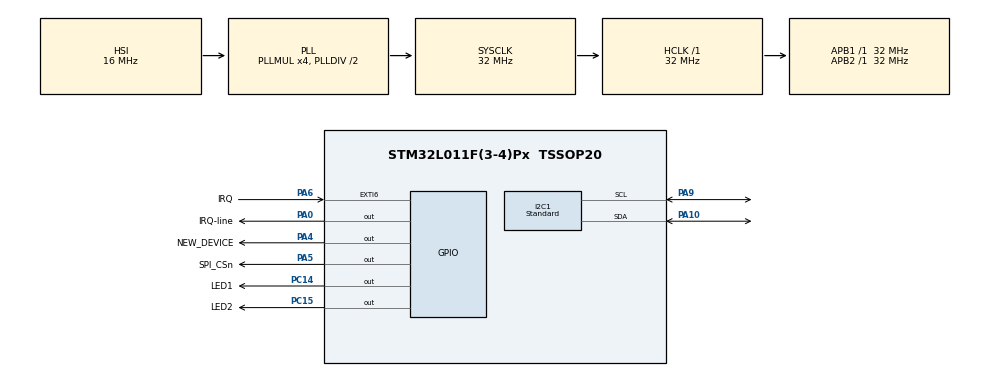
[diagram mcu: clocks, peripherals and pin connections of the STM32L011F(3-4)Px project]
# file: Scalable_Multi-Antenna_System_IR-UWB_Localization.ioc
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I2C1.GeneralCallMode=I2C_GENERALCALL_DISABLE
I2C1.I2C_Speed_Mode=I2C_Standard
I2C1.Timing=0x00707CBB
Mcu.Family=STM32L0
Mcu.Name=STM32L011F(3-4)Px
Mcu.Package=TSSOP20
NVIC.I2C1_IRQn=true\:0\:0\:false\:false\:true\:true\:true
PA0-CK_IN.GPIO_Label=IRQ-line
PA0-CK_IN.GPIO_ModeDefaultOutputPP=GPIO_MODE_OUTPUT_OD
PA0-CK_IN.Signal=GPIO_Output
PA10.Mode=I2C
PA10.Signal=I2C1_SDA
PA13.Mode=Serial_Wire
PA13.Signal=SYS_SWDIO
PA14.Mode=Serial_Wire
PA14.Signal=SYS_SWCLK
PA2.GPIO_Label=WAKEUP
PA2.Mode=SYS_WakeUp2
PA2.Signal=SYS_WKUP3
PA4.GPIO_Label=NEW_DEVICE
PA4.Signal=GPIO_Output
PA5.GPIO_Label=SPI_CSn
PA5.Signal=GPIO_Output
PA6.GPIO_Label=IRQ
PA6.Signal=GPXTI6
PA9.Mode=I2C
PA9.Signal=I2C1_SCL
PC14-OSC32_IN.GPIO_Label=LED1
PC14-OSC32_IN.Signal=GPIO_Output
PC15-OSC32_OUT.GPIO_Label=LED2
PC15-OSC32_OUT.Signal=GPIO_Output
ProjectManager.HeapSize=0x200
ProjectManager.StackSize=0x400
ProjectManager.TargetToolchain=STM32CubeIDE
RCC.AHBFreq_Value=32000000
RCC.APB1Freq_Value=32000000
RCC.APB1TimFreq_Value=32000000
RCC.APB2Freq_Value=32000000
RCC.APB2TimFreq_Value=32000000
RCC.HCLKFreq_Value=32000000
RCC.HSE_VALUE=8000000
RCC.HSI16_VALUE=16000000
RCC.HSI_VALUE=16000000
RCC.LSE_VALUE=32768
RCC.MSI_VALUE=2097000
RCC.PLLMUL=RCC_PLLMUL_4
RCC.SYSCLKFreq_VALUE=32000000
RCC.SYSCLKSource=RCC_SYSCLKSOURCE_PLLCLK
RCC.VCOOutputFreq_Value=64000000
board=custom

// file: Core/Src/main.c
/* USER CODE BEGIN Header */
/**
  ******************************************************************************
  * @file           : main.c
  * @brief          : Main program body
  ******************************************************************************
  * @attention
  *
  * <h2><center>&copy; Copyright (c) 2022 STMicroelectronics.
  * All rights reserved.</center></h2>
  *
  * This software component is licensed by ST under BSD 3-Clause license,
  * the "License"; You may not use this file except in compliance with the
  * License. You may obtain a copy of the License at:
  *                        opensource.org/licenses/BSD-3-Clause
  *
  ******************************************************************************
  */
/* USER CODE END Header */
#include "main.h"

I2C_HandleTypeDef hi2c1;

void SystemClock_Config(void);
static void MX_GPIO_Init(void);
static void MX_I2C1_Init(void);
/* USER CODE BEGIN PFP */

void HAL_GPIO_EXTI_Callback(uint16_t);

/* USER CODE END PFP */

int main(void)
{

  /* MCU Configuration--------------------------------------------------------*/

  /* Reset of all peripherals, Initializes the Flash interface and the Systick. */
  HAL_Init();

  /* Configure the system clock */
  SystemClock_Config();

  /* Initialize all configured peripherals */
  MX_GPIO_Init();
  MX_I2C1_Init();
  /* USER CODE BEGIN 2 */

  HAL_GPIO_WritePin(LED1_GPIO_Port, LED1_Pin, GPIO_PIN_RESET);
  HAL_GPIO_WritePin(LED2_GPIO_Port, LED2_Pin, GPIO_PIN_RESET);

  /* USER CODE END 2 */

  /* Infinite loop */
  while (1)
  {
	  /* TEST CODE: BLINK LEDS */
	  HAL_Delay(1000);
	  HAL_GPIO_TogglePin(LED1_GPIO_Port, LED1_Pin);
	  HAL_GPIO_TogglePin(LED2_GPIO_Port, LED2_Pin);

  }
}

void SystemClock_Config(void)
{
  RCC_OscInitTypeDef RCC_OscInitStruct = {0};
  RCC_ClkInitTypeDef RCC_ClkInitStruct = {0};
  RCC_PeriphCLKInitTypeDef PeriphClkInit = {0};

  /** Configure the main internal regulator output voltage
  */
  __HAL_PWR_VOLTAGESCALING_CONFIG(PWR_REGULATOR_VOLTAGE_SCALE1);
  /** Initializes the RCC Oscillators according to the specified parameters
  * in the RCC_OscInitTypeDef structure.
  */
  RCC_OscInitStruct.OscillatorType = RCC_OSCILLATORTYPE_HSI;
  RCC_OscInitStruct.HSIState = RCC_HSI_ON;
  RCC_OscInitStruct.HSICalibrationValue = RCC_HSICALIBRATION_DEFAULT;
  RCC_OscInitStruct.PLL.PLLState = RCC_PLL_ON;
  RCC_OscInitStruct.PLL.PLLSource = RCC_PLLSOURCE_HSI;
  RCC_OscInitStruct.PLL.PLLMUL = RCC_PLLMUL_4;
  RCC_OscInitStruct.PLL.PLLDIV = RCC_PLLDIV_2;
  if (HAL_RCC_OscConfig(&RCC_OscInitStruct) != HAL_OK)
  {
    Error_Handler();
  }
  /** Initializes the CPU, AHB and APB buses clocks
  */
  RCC_ClkInitStruct.ClockType = RCC_CLOCKTYPE_HCLK|RCC_CLOCKTYPE_SYSCLK
                              |RCC_CLOCKTYPE_PCLK1|RCC_CLOCKTYPE_PCLK2;
  RCC_ClkInitStruct.SYSCLKSource = RCC_SYSCLKSOURCE_PLLCLK;
  RCC_ClkInitStruct.AHBCLKDivider = RCC_SYSCLK_DIV1;
  RCC_ClkInitStruct.APB1CLKDivider = RCC_HCLK_DIV1;
  RCC_ClkInitStruct.APB2CLKDivider = RCC_HCLK_DIV1;

  if (HAL_RCC_ClockConfig(&RCC_ClkInitStruct, FLASH_LATENCY_1) != HAL_OK)
  {
    Error_Handler();
  }
  PeriphClkInit.PeriphClockSelection = RCC_PERIPHCLK_I2C1;
  PeriphClkInit.I2c1ClockSelection = RCC_I2C1CLKSOURCE_PCLK1;
  if (HAL_RCCEx_PeriphCLKConfig(&PeriphClkInit) != HAL_OK)
  {
    Error_Handler();
  }
}

static void MX_I2C1_Init(void)
{

  hi2c1.Instance = I2C1;
  hi2c1.Init.Timing = 0x00707CBB;
  hi2c1.Init.OwnAddress1 = 0;
  hi2c1.Init.AddressingMode = I2C_ADDRESSINGMODE_7BIT;
  hi2c1.Init.DualAddressMode = I2C_DUALADDRESS_DISABLE;
  hi2c1.Init.OwnAddress2 = 0;
  hi2c1.Init.OwnAddress2Masks = I2C_OA2_NOMASK;
  hi2c1.Init.GeneralCallMode = I2C_GENERALCALL_DISABLE;
  hi2c1.Init.NoStretchMode = I2C_NOSTRETCH_DISABLE;
  if (HAL_I2C_Init(&hi2c1) != HAL_OK)
  {
    Error_Handler();
  }
  /** Configure Analogue filter
  */
  if (HAL_I2CEx_ConfigAnalogFilter(&hi2c1, I2C_ANALOGFILTER_ENABLE) != HAL_OK)
  {
    Error_Handler();
  }
  /** Configure Digital filter
  */
  if (HAL_I2CEx_ConfigDigitalFilter(&hi2c1, 0) != HAL_OK)
  {
    Error_Handler();
  }

}

static void MX_GPIO_Init(void)
{
  GPIO_InitTypeDef GPIO_InitStruct = {0};

  /* GPIO Ports Clock Enable */
  __HAL_RCC_GPIOC_CLK_ENABLE();
  __HAL_RCC_GPIOA_CLK_ENABLE();

  /*Configure GPIO pin Output Level */
  HAL_GPIO_WritePin(GPIOC, LED1_Pin|LED2_Pin, GPIO_PIN_RESET);

  /*Configure GPIO pin Output Level */
  HAL_GPIO_WritePin(GPIOA, IRQ_line_Pin|NEW_DEVICE_Pin|SPI_CSn_Pin, GPIO_PIN_RESET);

  /*Configure GPIO pins : LED1_Pin LED2_Pin */
  GPIO_InitStruct.Pin = LED1_Pin|LED2_Pin;
  GPIO_InitStruct.Mode = GPIO_MODE_OUTPUT_PP;
  GPIO_InitStruct.Pull = GPIO_NOPULL;
  GPIO_InitStruct.Speed = GPIO_SPEED_FREQ_LOW;
  HAL_GPIO_Init(GPIOC, &GPIO_InitStruct);

  /*Configure GPIO pin : IRQ_line_Pin */
  GPIO_InitStruct.Pin = IRQ_line_Pin;
  GPIO_InitStruct.Mode = GPIO_MODE_OUTPUT_OD;
  GPIO_InitStruct.Pull = GPIO_NOPULL;
  GPIO_InitStruct.Speed = GPIO_SPEED_FREQ_LOW;
  HAL_GPIO_Init(IRQ_line_GPIO_Port, &GPIO_InitStruct);

  /*Configure GPIO pins : NEW_DEVICE_Pin SPI_CSn_Pin */
  GPIO_InitStruct.Pin = NEW_DEVICE_Pin|SPI_CSn_Pin;
  GPIO_InitStruct.Mode = GPIO_MODE_OUTPUT_PP;
  GPIO_InitStruct.Pull = GPIO_NOPULL;
  GPIO_InitStruct.Speed = GPIO_SPEED_FREQ_LOW;
  HAL_GPIO_Init(GPIOA, &GPIO_InitStruct);

  /*Configure GPIO pin : IRQ_Pin */
  GPIO_InitStruct.Pin = IRQ_Pin;
  GPIO_InitStruct.Mode = GPIO_MODE_IT_RISING;
  GPIO_InitStruct.Pull = GPIO_NOPULL;
  HAL_GPIO_Init(IRQ_GPIO_Port, &GPIO_InitStruct);

}

/* USER CODE BEGIN 4 */

/* Callback external interrupts */
void HAL_GPIO_EXTI_Callback(uint16_t GPIO_Pin){

	switch(GPIO_Pin){
		case IRQ_Pin:
			// do stuff
			break;

		case IRQ_Pin:
			// do stuff
			break;
	}
}

void HAL_I2C_MasterTxCpltCallback (I2C_HandleTypeDef * hi2c)
{
  /* When
   * HAL_I2C_Master_Transmit_IT (I2C_HandleTypeDef * hi2c, uint16_t DevAddress, uint8_t * pData, uint16_t Size);
   * is called and after completion, this function will be called and executed.
   * If you’d like to do something upon data transmission completion, then add this to your code in the application source file (main.c).
	*/
}

/* USER CODE END 4 */

void Error_Handler(void)
{
  __disable_irq();
  while (1)
  {
  }
}

/************************ (C) COPYRIGHT STMicroelectronics *****END OF FILE****/
